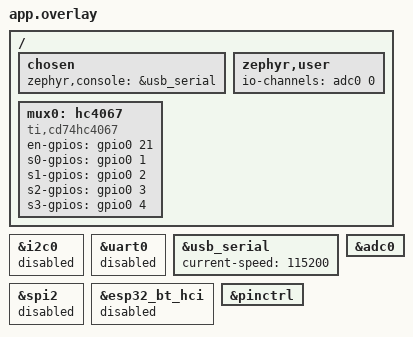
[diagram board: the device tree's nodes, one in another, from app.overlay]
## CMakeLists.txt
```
cmake_minimum_required(VERSION 3.20.0)

find_package(Zephyr REQUIRED HINTS $ENV{ZEPHYR_BASE})
project(analog_multiplexer_74hc4067)



# FILE(GLOB app_sources src/*.cpp)
FILE(GLOB app_sources src/main.cpp src/utils.cpp src/hc4067.cpp)
target_sources(app PRIVATE ${app_sources})
```

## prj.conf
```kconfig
# Kconfig - configuration options for the Zephyr Project


CONFIG_LOG_BACKEND_UART=y
CONFIG_LOG=y
CONFIG_LOG_MODE_DEFERRED=y
# CONFIG_LOG_DEFAULT_LEVEL=4

# Need float format support
CONFIG_REQUIRES_FULL_LIBC=y
CONFIG_REQUIRES_FLOAT_PRINTF=y
CONFIG_CBPRINTF_FP_SUPPORT=y

CONFIG_CPP=y
# CONFIG_CPLUSPLUS=y
# CONFIG_LIB_CPLUSPLUS=y
CONFIG_GLIBCXX_LIBCPP=y


CONFIG_REBOOT=y

CONFIG_MAIN_STACK_SIZE=4096
CONFIG_HEAP_MEM_POOL_SIZE=4096
CONFIG_SYSTEM_WORKQUEUE_STACK_SIZE=4096
CONFIG_ZVFS_OPEN_MAX=16
CONFIG_ZVFS_EVENTFD_MAX=16

##### DEBUG
# CONFIG_EARLY_CONSOLE=y
# CONFIG_DEBUG=y
# CONFIG_DEBUG_INFO=y
# CONFIG_NO_OPTIMIZATIONS=y
# THREAD_ANALYZER=y
# THREAD_ANALYZER_AUTO=y
# THREAD_ANALYZER_USE_PRINTK=y
# CONFIG_NET_IPV4_LOG_LEVEL_DBG=y
# CONFIG_DEBUG_OPTIMIZATIONS=y


CONFIG_UART_INTERRUPT_DRIVEN=y
CONFIG_SERIAL=y
CONFIG_GPIO=y
CONFIG_ADC=y
```

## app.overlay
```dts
&i2c0 {
    status = "disabled";
};
&uart0 {
    status = "disabled";
};
&usb_serial {
    status = "disabled";
};
&spi2 {
    status = "disabled";
};
&esp32_bt_hci {
    status = "disabled";
};


/ {
	

	chosen {
		/delete-property/ zephyr,shell-uart;
		        
        zephyr,console=&usb_serial;

	};
};


&usb_serial {
    status = "okay";
    current-speed = <115200>;

};


&pinctrl {
	
};


&adc0 {
	status = "okay";
};

/ {
    zephyr,user {
        /* Use ADC0 channel 0 for SIG (GPIO0 on ESP32-C3) */
        io-channels = <&adc0 0>;
    };
    mux0: hc4067 {
		compatible = "ti,cd74hc4067";
        /* Enable is active-low on part, but we drive raw levels via *_dt calls.
           Keeping ACTIVE_HIGH here for straightforward logical mapping (1 => high). */
		en-gpios = <&gpio0 21 GPIO_ACTIVE_HIGH>;
		s0-gpios = <&gpio0 1 GPIO_ACTIVE_HIGH>;
		s1-gpios = <&gpio0 2 GPIO_ACTIVE_HIGH>;
		s2-gpios = <&gpio0 3 GPIO_ACTIVE_HIGH>;
        s3-gpios = <&gpio0 4 GPIO_ACTIVE_HIGH>;
		status = "okay";
	};
};
```

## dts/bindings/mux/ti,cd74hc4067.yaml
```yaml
# Copyright 2025
# SPDX-License-Identifier: Apache-2.0

title: TI CD74HC4067 16-channel analog multiplexer

description: |
  Control interface for the CD74HC4067 analog multiplexer/demultiplexer.
  This binding models the digital control pins (EN, S0..S3) as GPIOs.

compatible: "ti,cd74hc4067"

include: base.yaml

properties:
  en-gpios:
    type: phandle-array
    required: true
    description: Enable pin (active low on the device)

  s0-gpios:
    type: phandle-array
    required: true
    description: Select bit 0 (LSB)

  s1-gpios:
    type: phandle-array
    required: true
    description: Select bit 1

  s2-gpios:
    type: phandle-array
    required: true
    description: Select bit 2

  s3-gpios:
    type: phandle-array
    required: true
    description: Select bit 3 (MSB)
```

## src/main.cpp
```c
#include <zephyr/kernel.h>
#include <zephyr/device.h>
#include <stdio.h>
#include <errno.h>
#include <zephyr/drivers/uart.h>
#define LOG_LEVEL CONFIG_LOG_DEFAULT_LEVEL
#include <zephyr/logging/log.h>
#include "hc4067.h"
#include <zephyr/devicetree.h>
#include <zephyr/drivers/gpio.h>
#include <zephyr/drivers/adc.h>
LOG_MODULE_REGISTER(app);

using namespace std;

int main_tick_interval = 100;



int main(void)
{
    /* Construct HC4067 directly from Devicetree */
    HC4067_INIT_FROM_DT_NODELABEL(mux, mux0);
    const struct device *adc_dev = DEVICE_DT_GET(DT_IO_CHANNELS_CTLR(DT_PATH(zephyr_user)));
    adc_channel_cfg adc_cfg = {};
    adc_cfg.gain = ADC_GAIN_1_4;
    adc_cfg.reference = ADC_REF_INTERNAL;
    adc_cfg.acquisition_time = ADC_ACQ_TIME_DEFAULT;
    adc_cfg.channel_id = DT_IO_CHANNELS_INPUT(DT_PATH(zephyr_user));
    adc_cfg.differential = 0;
    
    if (!mux.initialize()) {
        LOG_ERR("Failed to initialize HC4067 mux");
        return -EIO;
    }
    mux.set_enabled(true);
    if (!device_is_ready(adc_dev)) {
        LOG_ERR("ADC device not ready");
        return -EIO;
    }
    if (!mux.configure_adc(adc_dev, adc_cfg, 12)) {
        LOG_ERR("Failed to configure ADC in mux driver");
        return -EIO;
    }
    
    LOG_INF("HC4067 initialized and enabled");
    
    while (1) {
        char line[256];
        int16_t sample;
        int ofs = 0;
        for (uint8_t ch = 0; ch < 3; ++ch) {
            int ret = mux.read_channel_adc(ch, sample);
            int value = ret == 0 ? (int)sample : -1;
            ofs += snprintf(&line[ofs], sizeof(line) - ofs, "%d", value);
            if (ch != 15 && ofs < (int)sizeof(line) - 2) {
                line[ofs++] = ' ';
            }
        }
        line[ofs] = '\0';
        LOG_INF("%s", line);
        k_sleep(K_MSEC(main_tick_interval));
    }
    
	return 0;
}
```

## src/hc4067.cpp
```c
#include "hc4067.h"

#include <zephyr/logging/log.h>
LOG_MODULE_REGISTER(hc4067, CONFIG_LOG_DEFAULT_LEVEL);
#include <errno.h>

HC4067::HC4067(const gpio_dt_spec &select0,
	           const gpio_dt_spec &select1,
	           const gpio_dt_spec &select2,
	           const gpio_dt_spec &select3,
	           const gpio_dt_spec &enablePin)
	: s0(select0), s1(select1), s2(select2), s3(select3), en(enablePin) {}

int HC4067::configure_output_pin(const gpio_dt_spec &spec, gpio_flags_t extra_flags)
{
    if (!device_is_ready(spec.port)) {
        LOG_ERR("GPIO port not ready");
        return -ENODEV;
    }
    int rc = gpio_pin_configure_dt(&spec, GPIO_OUTPUT_INACTIVE | extra_flags);
    if (rc != 0) {
        LOG_ERR("Failed to configure GPIO %d rc=%d", spec.pin, rc);
    }
    return rc;
}

bool HC4067::initialize()
{
	int rc = 0;
	rc |= configure_output_pin(s0);
	rc |= configure_output_pin(s1);
	rc |= configure_output_pin(s2);
	rc |= configure_output_pin(s3);
	rc |= configure_output_pin(en);
	if (rc != 0) {
		return false;
	}

    /* Disable by default (EN high for HC4067 is disable) */
    gpio_pin_set_dt(&en, 1);
	enabled = false;
	activeChannel = 0;
	initialized = true;
	return true;
}

void HC4067::set_enabled(bool doEnable)
{
	if (!initialized) return;
    /* HC4067 enable is active LOW: set 0 to enable, 1 to disable */
    gpio_pin_set_dt(&en, doEnable ? 0 : 1);
	enabled = doEnable;
}

int HC4067::select_channel(uint8_t channel)
{
	if (!initialized) return -EINVAL;
	if (channel > 15) return -EINVAL;

    /* Set S0..S3 according to channel LSB..MSB */
    gpio_pin_set_dt(&s0, (channel >> 0) & 0x1);
    gpio_pin_set_dt(&s1, (channel >> 1) & 0x1);
    gpio_pin_set_dt(&s2, (channel >> 2) & 0x1);
    gpio_pin_set_dt(&s3, (channel >> 3) & 0x1);

	activeChannel = channel;

    /* Allow short settling time for the analog switch */
    k_busy_wait(100); /* settle longer for ADC sampling */
	return 0;
}

bool HC4067::configure_adc(const struct device *adc_device,
                           const adc_channel_cfg &channel_cfg_in,
                           uint8_t resolution_bits)
{
    if (adc_device == nullptr || !device_is_ready(adc_device)) {
        LOG_ERR("ADC device not ready");
        return false;
    }

    adcDev = adc_device;
    adcChannelId = channel_cfg_in.channel_id;
    adcResolutionBits = resolution_bits;

    adc_channel_cfg channel_cfg = channel_cfg_in;

    int rc = adc_channel_setup(adcDev, &channel_cfg);
    if (rc) {
        LOG_ERR("adc_channel_setup failed: %d", rc);
        return false;
    }
    return true;
}

int HC4067::read_channel_adc(uint8_t channel, int16_t &out_sample)
{
    if (!initialized) return -EINVAL;
    if (adcDev == nullptr) return -ENODEV;
    int sel = select_channel(channel);
    if (sel != 0) return sel;

    adc_sequence seq = {};
    seq.channels = BIT(adcChannelId);
    seq.buffer = &out_sample;
    seq.buffer_size = sizeof(out_sample);
    seq.resolution = adcResolutionBits;

    int rc = adc_read(adcDev, &seq);
    return rc;
}
```

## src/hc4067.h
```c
#ifndef __HC4067_H__
#define __HC4067_H__

#include <zephyr/kernel.h>
#include <zephyr/device.h>
#include <zephyr/devicetree.h>
#include <zephyr/drivers/gpio.h>
#include <zephyr/drivers/adc.h>

/* Convenience macros to construct an HC4067 instance directly from DT */
#define HC4067_INIT_FROM_DT_NODE(var_name, node_id) \
    HC4067 var_name( \
        GPIO_DT_SPEC_GET(node_id, s0_gpios), \
        GPIO_DT_SPEC_GET(node_id, s1_gpios), \
        GPIO_DT_SPEC_GET(node_id, s2_gpios), \
        GPIO_DT_SPEC_GET(node_id, s3_gpios), \
        GPIO_DT_SPEC_GET(node_id, en_gpios))

#define HC4067_INIT_FROM_DT_NODELABEL(var_name, node_label) \
    HC4067_INIT_FROM_DT_NODE(var_name, DT_NODELABEL(node_label))

class HC4067 {
public:
	HC4067(const gpio_dt_spec &select0,
	       const gpio_dt_spec &select1,
	       const gpio_dt_spec &select2,
	       const gpio_dt_spec &select3,
	       const gpio_dt_spec &enablePin);

	bool initialize();
	void set_enabled(bool enabled);
	int select_channel(uint8_t channel);

    /* ADC integration: caller provides full channel config; driver applies it
     * and stores channel id and resolution. */
    bool configure_adc(const struct device *adc_device,
                      const adc_channel_cfg &channel_cfg,
                      uint8_t resolution_bits = 12);
	int read_channel_adc(uint8_t channel, int16_t &out_sample);

	bool is_initialized() const { return initialized; }
	bool is_enabled() const { return enabled; }
	uint8_t current_channel() const { return activeChannel; }

private:
	gpio_dt_spec s0;
	gpio_dt_spec s1;
	gpio_dt_spec s2;
	gpio_dt_spec s3;
	gpio_dt_spec en;

	bool initialized = false;
	bool enabled = false;
	uint8_t activeChannel = 0;

	const struct device *adcDev = nullptr;
	uint8_t adcChannelId = 0;
	uint8_t adcResolutionBits = 12;

	static int configure_output_pin(const gpio_dt_spec &spec, gpio_flags_t extra_flags = 0);
};

#endif // __HC4067_H__
```

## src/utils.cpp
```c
#include "utils.h"


std::string shortest_float(float f) {
    if (f == 0.0f) return "0";
    if (f != f) return "NaN";
    // if (f == INFINITY) return "inf";
    // if (f == -INFINITY) return "-inf";

    // Use snprintf with %.9g for float32 round-trip safety
    // This is sufficient for IEEE-754 float32
    char buf[32];
    snprintf(buf, sizeof(buf), "%.9g", f);
    return std::string(buf);
}
```

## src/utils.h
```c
#ifndef __UTILS_H__
#define __UTILS_H__

#include <string>


std::string shortest_float(float f);

#endif // __UTILS_H__
```
